# DMASS_BCDMA_0_DMASS_BCDMA_0_BCDMA_GCFG_485C4000h register map
Vendor: Texas Instruments
Peripheral module from a debugger description file (folder am62L).
Registers are 32-bit, read-only, reset 0x0 unless marked. A register's access mark holds for its fields unless they carry their own. Offsets are as the file gives them; lines under a group give offsets from that group; [hi:lo] are bit positions; {n}, {i} and the like mark numbered series; 'fields as' and 'values as' point back to an identical list; <NAME> marks a mode.

## DMASS_BCDMA_0_BCDMA_GCFG
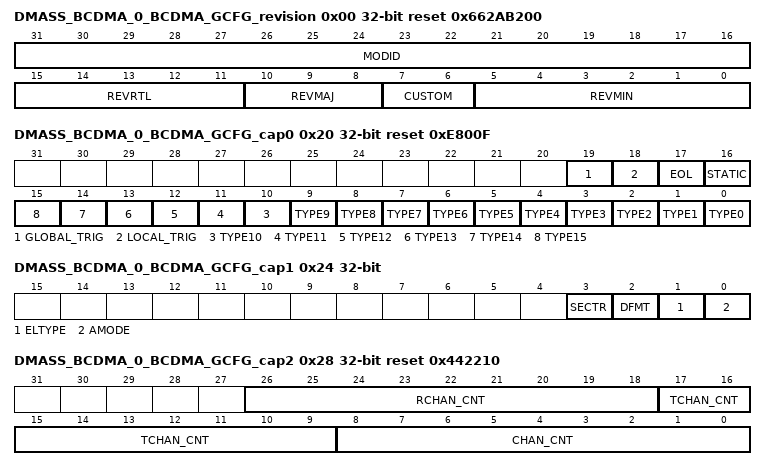
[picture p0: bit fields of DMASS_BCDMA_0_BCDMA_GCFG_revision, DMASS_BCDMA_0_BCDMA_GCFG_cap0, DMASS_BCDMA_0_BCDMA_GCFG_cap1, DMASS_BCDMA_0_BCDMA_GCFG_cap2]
0x00 DMASS_BCDMA_0_BCDMA_GCFG_revision reset 0x662AB200 — The Revision Register contains the major and minor revisions for the module.
  [31:16] MODID — Module ID field Reset Source: rst_mod_g_rst_n
  [15:11] REVRTL — RTL revision. Will vary depending on release. Reset Source: rst_mod_g_rst_n
  [10:8] REVMAJ — Major revision Reset Source: rst_mod_g_rst_n
  [7:6] CUSTOM — Custom Reset Source: rst_mod_g_rst_n
  [5:0] REVMIN — Minor revision Reset Source: rst_mod_g_rst_n
0x20 DMASS_BCDMA_0_BCDMA_GCFG_cap0 reset 0xE800F — The Capabilities Register 0 specifies which standard features this BCDMA instance supports.
  [19] GLOBAL_TRIG — Global triggers 0 and 1 are supported Reset Source: rst_mod_g_rst_n
  [18] LOCAL_TRIG — Dedicated local trigger is supported Reset Source: rst_mod_g_rst_n
  [17] EOL — EOL field is supported Reset Source: rst_mod_g_rst_n
  [16] STATIC — STATIC field is supported Reset Source: rst_mod_g_rst_n
  [n] TYPE{n} (n=0..15) — Type {n} TR is supported Reset Source: rst_mod_g_rst_n
0x24 DMASS_BCDMA_0_BCDMA_GCFG_cap1 — The Capabilities Register 1 specifies which standard features this BCDMA instance supports.
  [3] SECTR — Maximum second TR function that is supported Reset Source: rst_mod_g_rst_n
  [2] DFMT — Maximum data reformatting function that is supported Reset Source: rst_mod_g_rst_n
  [1] ELTYPE — Maximum element type value that is supported. Reset Source: rst_mod_g_rst_n
  [0] AMODE — The maximum AMODE that is supported. If AMODE is supported then DIR field must be supported for that AMODE. Reset Source: rst_mod_g_rst_n
0x28 DMASS_BCDMA_0_BCDMA_GCFG_cap2 reset 0x442210 — The Capabilities Register 2 specifies how many resources this BCDMA instance supports.
  [26:18] RCHAN_CNT — Rx split channel count including high capacity and ultra high capacity Reset Source: rst_mod_g_rst_n
  [17:9] TCHAN_CNT — Tx split channel count including high capacity and ultra high capacity Reset Source: rst_mod_g_rst_n
  [8:0] CHAN_CNT — BC channel count including high capacity and ultra high capacity Reset Source: rst_mod_g_rst_n
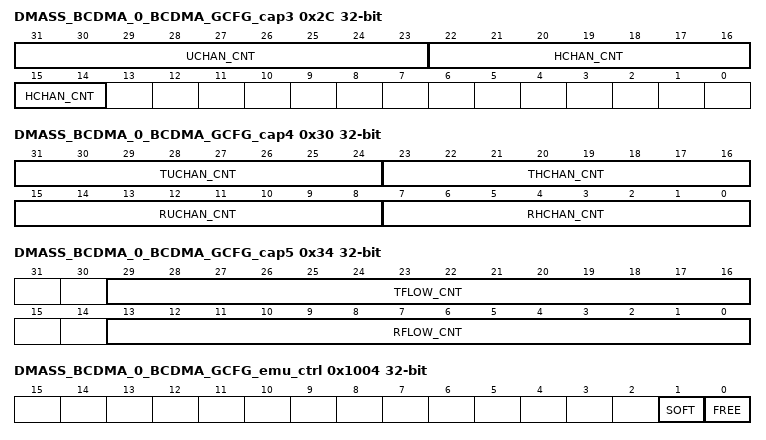
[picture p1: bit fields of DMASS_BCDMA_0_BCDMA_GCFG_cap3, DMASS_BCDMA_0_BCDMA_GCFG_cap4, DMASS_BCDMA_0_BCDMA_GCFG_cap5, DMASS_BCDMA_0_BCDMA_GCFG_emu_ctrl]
0x2C DMASS_BCDMA_0_BCDMA_GCFG_cap3 — The Capabilities Register 3 specifies how many resources this BCDMA instance supports.
  [31:23] UCHAN_CNT — BC ultra high capacity internal channel count Reset Source: rst_mod_g_rst_n
  [22:14] HCHAN_CNT — BC high capacity internal channel count Reset Source: rst_mod_g_rst_n
0x30 DMASS_BCDMA_0_BCDMA_GCFG_cap4 — The Capabilities Register 4 specifies how many resources this BCDMA instance supports.
  [31:24] TUCHAN_CNT — TX ultra high capacity internal channel count Reset Source: rst_mod_g_rst_n
  [23:16] THCHAN_CNT — TX high capacity internal channel count Reset Source: rst_mod_g_rst_n
  [15:8] RUCHAN_CNT — RX ultra high capacity internal channel count Reset Source: rst_mod_g_rst_n
  [7:0] RHCHAN_CNT — RX high capacity internal channel count Reset Source: rst_mod_g_rst_n
0x34 DMASS_BCDMA_0_BCDMA_GCFG_cap5 — The Capabilities Register 5 specifies how many flows this BCDMA instance supports.
  [29:16] TFLOW_CNT — Tx flow table entry count Reset Source: rst_mod_g_rst_n
  [13:0] RFLOW_CNT — Rx flow table entry count Reset Source: rst_mod_g_rst_n
0x1000 DMASS_BCDMA_0_BCDMA_GCFG_perf_ctrl rw reset 0x40 — The performance control register contains fields which can be used to adjust the performance of the BCDMA in the system.
  [15:0] TIMEOUT_CNT — This feature is not currently supported. Reset Source: rst_mod_g_rst_n
0x1004 DMASS_BCDMA_0_BCDMA_GCFG_emu_ctrl rw — The emulation control register is used to control the behavior of the DMA when the emususp input is asserted.
  [1] SOFT — Soft Reset Source: rst_mod_g_rst_n
  [0] FREE — Free Reset Source: rst_mod_g_rst_n
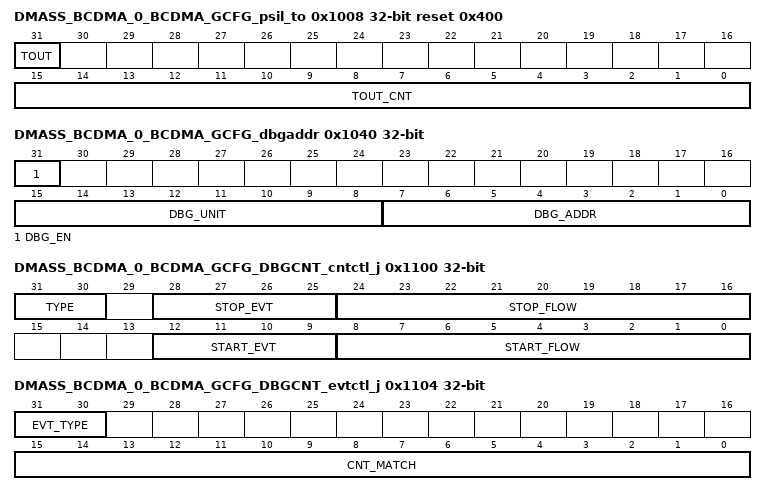
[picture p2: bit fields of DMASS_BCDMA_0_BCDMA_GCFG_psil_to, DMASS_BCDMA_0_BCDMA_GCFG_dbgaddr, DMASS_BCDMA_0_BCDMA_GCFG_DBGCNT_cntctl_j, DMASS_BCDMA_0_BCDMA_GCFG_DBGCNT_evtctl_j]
0x1008 DMASS_BCDMA_0_BCDMA_GCFG_psil_to rw reset 0x400 — The PSI-L proxy timeout register controls the timeout watchdog and reports timeout occurrances on PSI-L configuration transactions issued by the built in PSI-L proxy.
  [31] TOUT — Timeout occurred. When set indicates that a timeout has occurred on a config access Reset Source: rst_mod_g_rst_n
  [15:0] TOUT_CNT — Timeout period. Specifies how many cycles to wait before closing up a conifiguration read or write transaction and asserting the tout bit Reset Source: rst_mod_g_rst_n
0x1040 DMASS_BCDMA_0_BCDMA_GCFG_dbgaddr rw — This register provides a writable address which allows debug information to be read from the Debug Data Register
  [31] DBG_EN — Debug enable Reset Source: rst_mod_g_rst_n
  [15:8] DBG_UNIT — Selects which unit to read debug information from 18 Read response tracking engine35 Write response tracking engine80 Scheduling configuration engine176 TX scheduling unit 0177 TX scheduling unit 1178 TX scheduling unit 2179 TX scheduling unit 3192 RX scheduling unit 0193 RX scheduling unit 1194 RX scheduling unit 2195 RX scheduling unit 3
  [7:0] DBG_ADDR — Selects offset within unit to access seperate debug registers Reset Source: rst_mod_g_rst_n
0x1044 DMASS_BCDMA_0_BCDMA_GCFG_dbgdata access not given — This register provides read only debug data
  [31:0] DBG_DATA — Provides debug information from various internal units. The value which is read back depends on which unit and register are selected in the Debug Address Register Reset Source: rst_mod_g_rst_n (access R/NA)
0x1100 DMASS_BCDMA_0_BCDMA_GCFG_DBGCNT_cntctl_j rw — The debug counter control to select how the associated counter is incremented and starts and stops. Writing to this register will reset the counter.
  [31:30] TYPE — Selects what type of counter the Debug Counter is used. 0 Increment counter the start selected event increment the counter on each rising edge.1 One shot cycle count the first time the rising edge start count is generated and stops when the stop event rising edge is seen. If additional start events are seen the counter will not change. The counter will not roll over.2 Continous cycle count the counter counts cycles when start event rising edge is seen and stops when stop rising edge is seen and starts again when the start event rising edge is seen. The counter will not roll over.
  [28:25] STOP_EVT — The event type to use for the timer. The event will be the event from the given flow in the stop flow field. 0 A scheduling request is sent to a scheduling unit for the flow1 A read command is sent for the flow2 A write command is sent for the flow3 A read data response is received for the flow4 A write data response is received for the flow5 The read data response for the last request of the TR/PKT has been received6 The write data response for the last request of the TR/PKT has been received8
  [24:16] STOP_FLOW — The flow number that generates the event to start or increment the counter Reset Source: rst_mod_g_rst_n
  [12:9] START_EVT — The event type to use for the timer. The event will be the event from the given flow in the start flow field. 0 A scheduling request is sent to a scheduling unit for the flow1 A read command is sent for the flow2 A write command is sent for the flow3 A read data response is received for the flow4 A write data response is received for the flow5 The data read response for the last request of the TR/PKT has been received6 The data write response for the last request of the TR/PKT has been received8
  [8:0] START_FLOW — The flow number that generates the event to start or increment the counter Reset Source: rst_mod_g_rst_n
0x1104 DMASS_BCDMA_0_BCDMA_GCFG_DBGCNT_evtctl_j rw — The debug event control to select when the debug controller can issue an event that can be used by another debug event control. Writing to this register will reset the counter.
  [31:30] EVT_TYPE — Selects when or if an event will be generated by the counter. 0 No event is generated.1 Exact match.2 The counter is bit-wise ANDed with the cnt match and the event is when this mask is non-zero.
  [15:0] CNT_MATCH — The value that if set the counter generates an event. It can also be used as a mask based on event type Reset Source: rst_mod_g_rst_n
0x1108 DMASS_BCDMA_0_BCDMA_GCFG_DBGCNT_cnt_j — The actual counter that is incremented or free running based on the event control registers
  [15:0] CNT — The count value of the debug counter Reset Source: rst_mod_g_rst_n
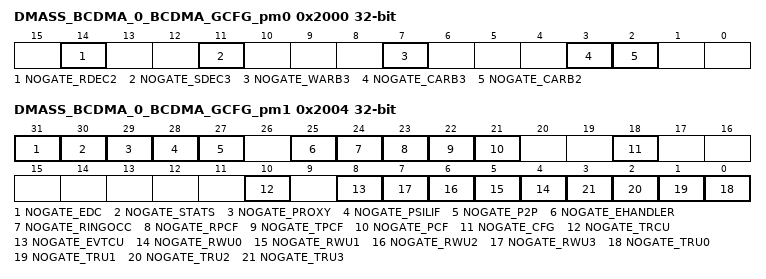
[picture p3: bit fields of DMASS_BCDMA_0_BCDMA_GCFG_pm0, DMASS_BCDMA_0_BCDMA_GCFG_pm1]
0x2000 DMASS_BCDMA_0_BCDMA_GCFG_pm0 rw — This register enables or inhibits automatic clock gating to individual sub-blocks
  [14] NOGATE_RDEC2 — When set inhibits automatic gating of clock to rdec2 submodule. Reset Source: rst_mod_g_rst_n
  [11] NOGATE_SDEC3 — When set inhibits automatic gating of clock to sdec3 submodule. Reset Source: rst_mod_g_rst_n
  [7] NOGATE_WARB3 — When set inhibits automatic gating of clock to warb3 submodule. Reset Source: rst_mod_g_rst_n
  [3] NOGATE_CARB3 — When set inhibits automatic gating of clock to carb3 submodule. Reset Source: rst_mod_g_rst_n
  [2] NOGATE_CARB2 — When set inhibits automatic gating of clock to carb2 submodule. Reset Source: rst_mod_g_rst_n
0x2004 DMASS_BCDMA_0_BCDMA_GCFG_pm1 rw — This register enables or inhibits automatic clock gating to individual sub-blocks
  [31] NOGATE_EDC — When set inhibits automatic gating of clock to edc submodule. Reset Source: rst_mod_g_rst_n
  [30] NOGATE_STATS — When set inhibits automatic gating of clock to stats submodule. Reset Source: rst_mod_g_rst_n
  [29] NOGATE_PROXY — When set inhibits automatic gating of clock to proxy submodule. Reset Source: rst_mod_g_rst_n
  [28] NOGATE_PSILIF — When set inhibits automatic gating of clock to psilif submodule. Reset Source: rst_mod_g_rst_n
  [27] NOGATE_P2P — When set inhibits automatic gating of clock to p2p submodule. Reset Source: rst_mod_g_rst_n
  [25] NOGATE_EHANDLER — When set inhibits automatic gating of clock to ehandler submodule. Reset Source: rst_mod_g_rst_n
  [24] NOGATE_RINGOCC — When set inhibits automatic gating of clock to ringocc submodule. Reset Source: rst_mod_g_rst_n
  [23] NOGATE_RPCF — When set inhibits automatic gating of clock to rpcf submodule. Reset Source: rst_mod_g_rst_n
  [22] NOGATE_TPCF — When set inhibits automatic gating of clock to tpcf submodule. Reset Source: rst_mod_g_rst_n
  [21] NOGATE_PCF — When set inhibits automatic gating of clock to pcf submodule. Reset Source: rst_mod_g_rst_n
  [18] NOGATE_CFG — When set inhibits automatic gating of clock to cfg submodule. Reset Source: rst_mod_g_rst_n
  [10] NOGATE_TRCU — When set inhibits automatic gating of clock to trcu submodule. Reset Source: rst_mod_g_rst_n
  [8] NOGATE_EVTCU — When set inhibits automatic gating of clock to evtcu submodule. Reset Source: rst_mod_g_rst_n
  [n+4] NOGATE_RWU{n} (n=0..3) — When set inhibits automatic gating of clock to rwu{n} submodule. Reset Source: rst_mod_g_rst_n
  [n] NOGATE_TRU{n} (n=0..3) — When set inhibits automatic gating of clock to tru{n} submodule. Reset Source: rst_mod_g_rst_n
